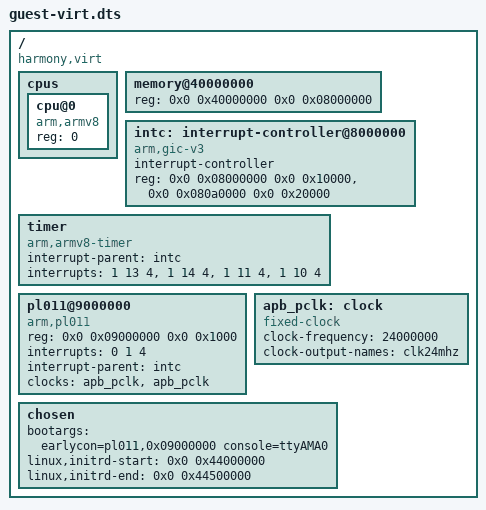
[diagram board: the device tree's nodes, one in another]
// SPDX-License-Identifier: GPL-2.0-or-later
//
// Device tree for the Harmony EL2 micro-VM virtual machine.
// One CPU, 128 MiB RAM, GICv3, PL011 UART with interrupt.

/dts-v1/;

/ {
	compatible = "harmony,virt";
	#address-cells = <2>;
	#size-cells = <2>;

	cpus {
		#address-cells = <1>;
		#size-cells = <0>;
		cpu@0 {
			device_type = "cpu";
			compatible = "arm,armv8";
			reg = <0>;
		};
	};

	memory@40000000 {
		device_type = "memory";
		reg = <0x0 0x40000000 0x0 0x08000000>;
	};

	intc: interrupt-controller@8000000 {
		compatible = "arm,gic-v3";
		#interrupt-cells = <3>;
		interrupt-controller;
		reg = <0x0 0x08000000 0x0 0x10000>,
		      <0x0 0x080a0000 0x0 0x20000>;
	};

	timer {
		compatible = "arm,armv8-timer";
		interrupt-parent = <&intc>;
		interrupts = <1 13 4>,  /* secure physical    PPI 29 */
		             <1 14 4>,  /* non-secure physical PPI 30 */
		             <1 11 4>,  /* virtual             PPI 27 */
		             <1 10 4>;  /* hypervisor          PPI 26 */
	};

	pl011@9000000 {
		compatible = "arm,pl011", "arm,primecell";
		reg = <0x0 0x09000000 0x0 0x1000>;
		interrupts = <0 1 4>;
		interrupt-parent = <&intc>;
		clock-names = "uartclk", "apb_pclk";
		clocks = <&apb_pclk>, <&apb_pclk>;
	};

	apb_pclk: clock {
		compatible = "fixed-clock";
		#clock-cells = <0>;
		clock-frequency = <24000000>;
		clock-output-names = "clk24mhz";
	};

	chosen {
		bootargs = "earlycon=pl011,0x09000000 console=ttyAMA0";
		linux,initrd-start = <0x0 0x44000000>;
		linux,initrd-end = <0x0 0x44500000>;
	};
};
